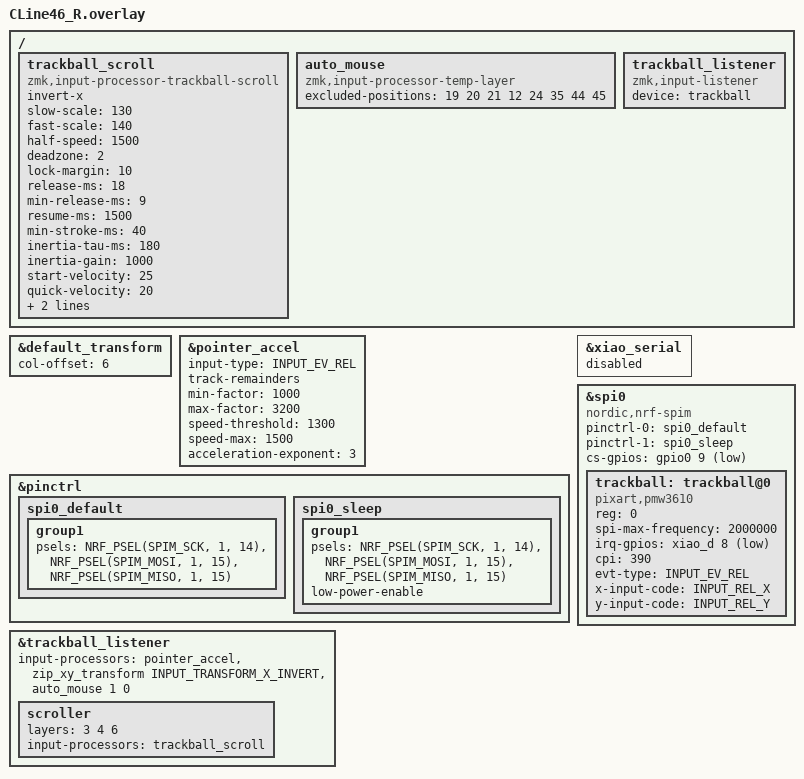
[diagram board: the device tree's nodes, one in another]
#include "CLine46.dtsi"
#include <zephyr/dt-bindings/input/input-event-codes.h>
#include <input/processors.dtsi>
#include <input/processors/runtime-input-processor.dtsi>
#include <dt-bindings/zmk/runtime_input_processor.h>
#include <behaviors/battery_history_request.dtsi>
#include <behaviors/input_gestures_accel.dtsi>

&default_transform {
    col-offset = <6>;
};

/* トラックボールのポインタ加速。カーソルを速く動かすほど移動量が
   大きくなる。値は千分率(1000=等倍)。cpi=390 前提の counts/sec。 */

&pointer_accel {
    input-type = <INPUT_EV_REL>;
    track-remainders;            // 端数を蓄積して精度低下を防ぐ

    min-factor = <1000>;          // ゆっくり動かした時は等倍(1.0x)
    max-factor = <3200>;         // 速く動かした時は最大3.2倍まで加速
    speed-threshold = <1300>;    // これ未満の速度では等倍(1.0x)
    speed-max = <1500>;          // これ以上の速度で最大倍率に到達
    acceleration-exponent = <3>; // 1=線形 / 2=二次関数的 / 3=三次関数的カーブ
};

/* スクロール。加速・軸固定・慣性をこれ1つで行う。センサー生値(cpi=390)を受け取る。
   実装: src/input_processor_trackball_scroll.c
   量の単位は milli-units/count (100 = 10カウントで1段)。
   慣性はゆっくり動かした時以外はほぼ常に付ける (start-velocity 未満の速さでは滑らない)。 */

/ {
    trackball_scroll: trackball_scroll {
        compatible = "zmk,input-processor-trackball-scroll";
        #input-processor-cells = <0>;
        invert-x;                    // 横スクロールの向きを反転
        // no-inertia;               // 有効にすると慣性なし (離したらすぐ止まる)

        slow-scale = <130>;          // ゆっくり転がした時: 約7.7カウントで1段
        fast-scale = <140>;          // 速く転がした時: 約7.1カウントで1段 (ゆるい加速)
        half-speed = <1500>;         // この速度(counts/sec)で slow と fast の中間
        deadzone = <2>;              // 動き出し・反転直後の2カウントは無視(触れただけで動かない)
        lock-margin = <10>;          // 縦固定。横がこれ以上はっきり勝ったら横に切り替え

        release-ms = <18>;           // 「離した」判定の最長時間(ゆっくり動かしている時)
        min-release-ms = <9>;        // 「離した」判定の最短時間(速く動かしている時)。直近の報告間隔の1.5倍で判定
        resume-ms = <1500>;          // この時間内に同じ向きへ触り直したら続きとして扱う(小刻みな操作の端数が積み重なる)
        min-stroke-ms = <40>;        // これ以上続けて転がした時だけ慣性を付ける
        inertia-tau-ms = <180>;      // 慣性の減速の時定数。滑る距離 ≒ 初速 × この時間
        inertia-gain = <1000>;       // 慣性の初速の倍率(千分率)。離す直前の減速分を補う
        start-velocity = <25>;       // 慣性の初速 = 離す直前の速度 - これ(段/秒)。ゆっくり以外はほぼ常に滑る
        quick-velocity = <20>;       // 初速がこれ(段/秒)未満の小さい慣性は、距離はそのまま素早く滑り終える(遅れをなくす)
        max-velocity = <150>;        // 慣性の初速の上限(段/秒)
        stop-velocity = <3>;         // この速度(段/秒)まで落ちたら終了
    };
};


/ {
    /* オートマウスレイヤー。タイムアウトは使わず(第2引数 0)、
       excluded-positions 以外のキーを押した時点で解除する。
       ZMK 標準の zip_temp_layer は excluded-positions が空だと
       キー押下による解除が一切働かないため、必ず指定すること
       (zmk/app/src/pointing/input_processor_temp_layer.c の
        handle_position_state_changed)。 */

    auto_mouse: auto_mouse {
        compatible = "zmk,input-processor-temp-layer";
        #input-processor-cells = <2>;

        //  19 20 21 44 45 : クリック / スクロール
        //  12 24 35       : Shift / Alt (クリックとの併用のため維持)
        //
        //  39 40 は除外しない。タップで Esc / 英数 を出すキーなので、
        //  Esc や IME 切り替えをしたらレイヤーを抜けるほうが自然なため。
        //  MOUSE レイヤーでは &trans なので、解除が先に走っても
        //  デフォルトレイヤーの同じバインディングに解決される。
        //  Cmd+クリックは位置44 45 のクリックで代替できる。
        //
        //  19 20 を除外リストから外すと「クリックしたらレイヤーを抜ける」に
        //  できそうだが、実機ではクリック自体が効かなくなる。
        //  processor_temp_layer のリスナーが keymap より先に走ってレイヤーを
        //  解除するため、&mkp が解決される前にベースレイヤーへ落ちてしまう。

        excluded-positions = <19 20 21 12 24 35 44 45>;
    };

    trackball_listener {
        status = "okay";
        compatible = "zmk,input-listener";
        device = <&trackball>;
    };
};

&pinctrl {
    spi0_default: spi0_default {
        group1 {
            psels = <NRF_PSEL(SPIM_SCK, 1, 14)>,
                <NRF_PSEL(SPIM_MOSI, 1, 15)>,
                <NRF_PSEL(SPIM_MISO, 1, 15)>;
        };
    };

    spi0_sleep: spi0_sleep {
        group1 {
            psels = <NRF_PSEL(SPIM_SCK, 1, 14)>,
                <NRF_PSEL(SPIM_MOSI, 1, 15)>,
                <NRF_PSEL(SPIM_MISO, 1, 15)>;
            low-power-enable;
        };
    };
};


&xiao_serial { status = "disabled"; };

&spi0 {
    status = "okay";
    compatible = "nordic,nrf-spim";
    pinctrl-0 = <&spi0_default>;
    pinctrl-1 = <&spi0_sleep>;
    pinctrl-names = "default", "sleep";
    cs-gpios = <&gpio0 9 GPIO_ACTIVE_LOW>;  //P0.09を指定(CS)

    trackball: trackball@0 {
        status = "okay";
        compatible = "pixart,pmw3610";
        reg = <0>;
        spi-max-frequency = <2000000>;
        irq-gpios = <&xiao_d 8 (GPIO_ACTIVE_LOW | GPIO_PULL_UP)>;
        cpi = <390>;   // カーソル速度。下げるほど遅くなる
        //swap-xy;
        evt-type = <INPUT_EV_REL>;
        x-input-code = <INPUT_REL_X>;
        y-input-code = <INPUT_REL_Y>;
    };
};

// Overrides for the input listener node
&trackball_listener {
    status = "okay";
    input-processors =
        <&pointer_accel>,                                   //ポインタ加速
        //<&zip_xy_transform INPUT_TRANSFORM_Y_INVERT>;     //Y軸反転
        //<&zip_xy_transform INPUT_TRANSFORM_XY_SWAP>,      //X軸とY軸の入れ替え
        <&zip_xy_transform INPUT_TRANSFORM_X_INVERT>,       //X軸反転
        <&auto_mouse 1 0>;                                  //トラックボール操作で MOUSE レイヤー(1)を有効化。0 = 自動解除なし


    scroller {
        layers = <3 4 6>;   // SYMBOL / SCROLL / FUNCTION レイヤー (keymap の #define SYMBOL / SCROLL / FUNCTION と合わせる)
        input-processors = <&trackball_scroll>;
    };
};
